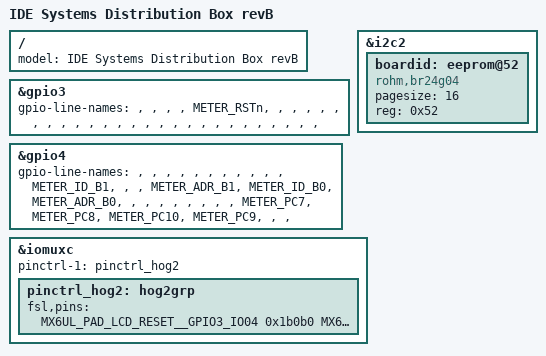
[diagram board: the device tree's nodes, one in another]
/*
 * Copyright (C) 2019 Amotus Solutions, Inc.
 */

/dts-v1/;

#include "imx6ull-dart6ul-ide.dtsi"

/ {
	model = "IDE Systems Distribution Box revB";
};

&gpio3 {
	gpio-line-names = "", "", "", "", "METER_RSTn", "", "", "",
	"", "", "", "", "", "", "", "",
	"", "", "", "", "", "", "", "",
	"", "", "", "", "", "", "", "";
};

&gpio4 {
	gpio-line-names = "", "", "", "", "", "", "", "",
	"", "", "", "METER_ID_B1", "", "", "METER_ADR_B1", "METER_ID_B0",
	"METER_ADR_B0", "", "", "", "", "", "", "",
	"", "METER_PC7", "METER_PC8", "METER_PC10", "METER_PC9", "", "", "";
};

&i2c2 {
	boardid: eeprom@52 {
		compatible = "rohm,br24g04", "atmel,24c04";
		pagesize = <16>;
		reg = <0x52>;
	};
};

&iomuxc {
	pinctrl-1 = <&pinctrl_hog2>;

	pinctrl_hog2: hog2grp {
		fsl,pins = <
		/* Meter gpios -- revB specific */
		MX6UL_PAD_LCD_RESET__GPIO3_IO04      0x1b0b0 /* J1-56: METER_RSTn   */
		MX6UL_PAD_NAND_CLE__GPIO4_IO15       0x1b0b0 /* J2-61: METER_ID_B0  */
		MX6UL_PAD_NAND_WP_B__GPIO4_IO11      0x1b0b0 /* J2-63: METER_ID_B1  */
		MX6UL_PAD_NAND_DQS__GPIO4_IO16       0x1b0b0 /* J1-62: METER_ADR_B0 */
		MX6UL_PAD_NAND_CE1_B__GPIO4_IO14     0x1b0b0 /* J1-58: METER_ADR_B1 */
		>;
	};
};
